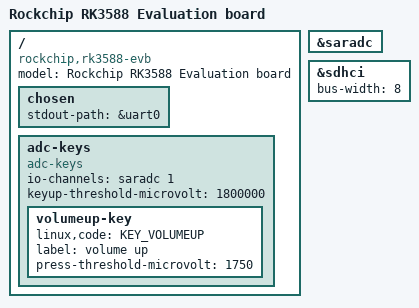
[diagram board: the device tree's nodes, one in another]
// SPDX-License-Identifier: (GPL-2.0+ OR MIT)
/*
 * Copyright (c) 2025 Rockchip Electronics Co., Ltd.
 */

/dts-v1/;
#include "rk3588.dtsi"
#include "rk3588-u-boot.dtsi"
#include <dt-bindings/input/input.h>

/ {
	model = "Rockchip RK3588 Evaluation board";
	compatible = "rockchip,rk3588-evb", "rockchip,rk3588";

	chosen {
		stdout-path = &uart0;
	};

	adc-keys {
		compatible = "adc-keys";
		io-channels = <&saradc 1>;
		io-channel-names = "buttons";
		keyup-threshold-microvolt = <1800000>;
		u-boot,dm-spl;
		status = "okay";

		volumeup-key {
			u-boot,dm-spl;
			linux,code = <KEY_VOLUMEUP>;
			label = "volume up";
			press-threshold-microvolt = <1750>;
		};
	};
};

&saradc {
	/delete-property/ u-boot,dm-pre-reloc;
	u-boot,dm-spl;
};

&sdhci {
	bus-width = <8>;
};
